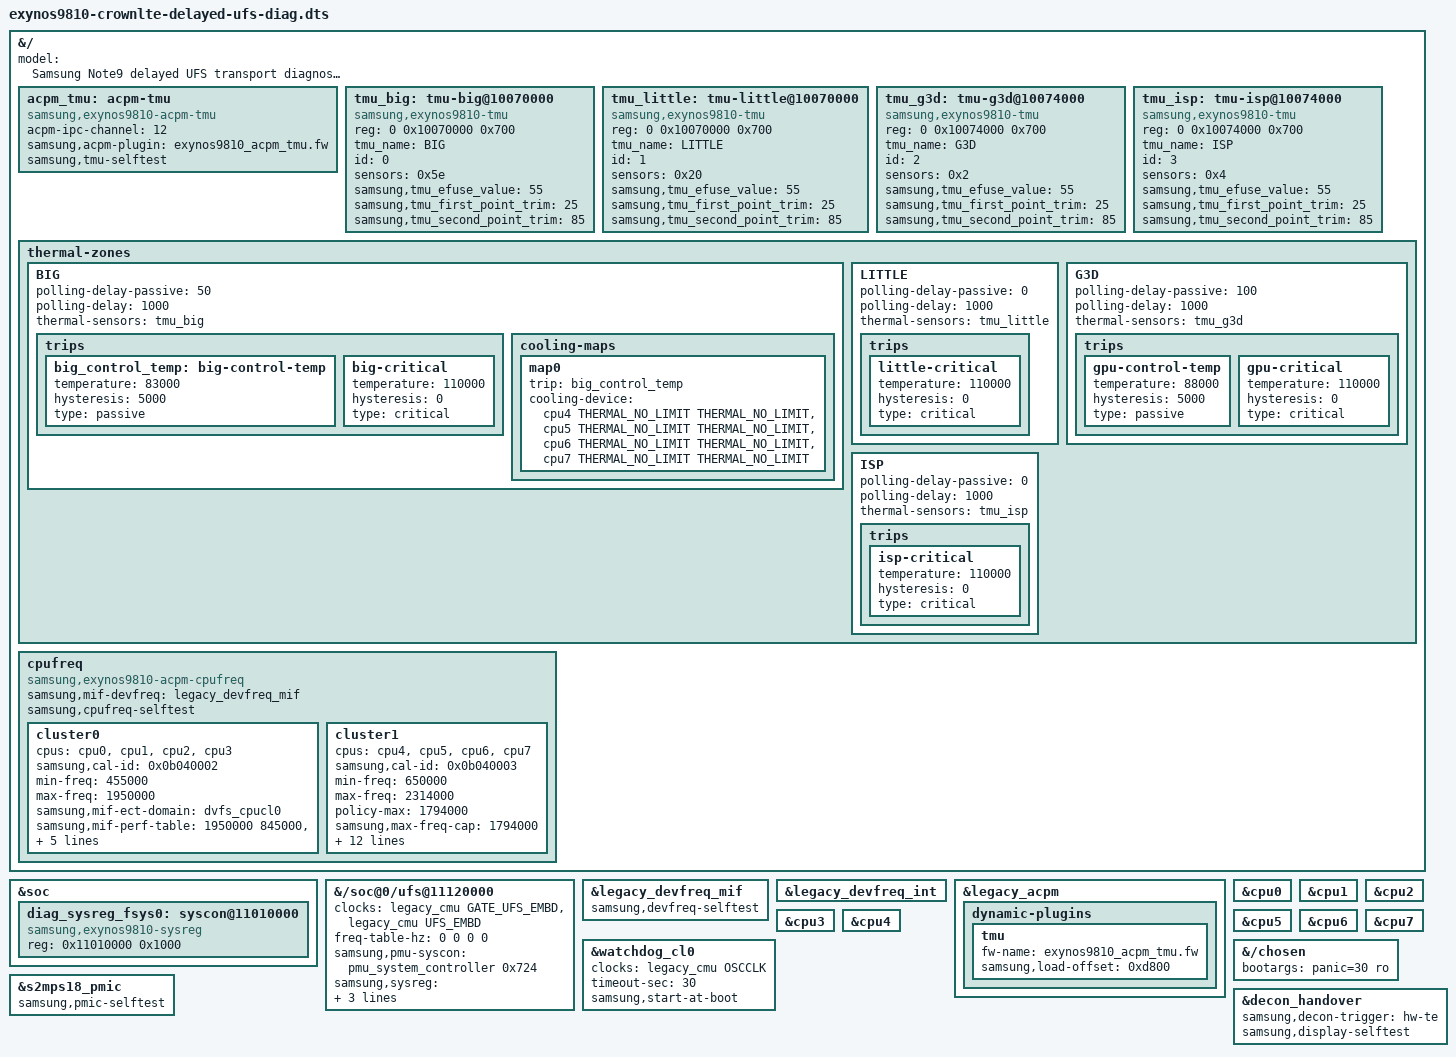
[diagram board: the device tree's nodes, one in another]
// SPDX-License-Identifier: GPL-2.0
/* First-probe gate and SCSI policy are mandatory. No Android init or mounts.
 * VCC and pad mux are inherited from sboot for this first transport test.
 * No regulator driver is enabled in the parent diagnostic configuration. */
#include "exynos9810-crownlte-real-clock-usb-diag.dts"
#include <dt-bindings/thermal/thermal.h>

&{/} {
	model = "Samsung Note9 delayed UFS transport diagnostic";
};
&soc {
	diag_sysreg_fsys0: syscon@11010000 {
		compatible = "samsung,exynos9810-sysreg", "syscon";
		reg = <0x11010000 0x1000>;
	};
};
&{/soc@0/ufs@11120000} {
	clocks = <&legacy_cmu GATE_UFS_EMBD>, <&legacy_cmu UFS_EMBD>;
	clock-names = "GATE_UFS_EMBD", "UFS_EMBD";
	freq-table-hz = <0 0 0 0>;
	samsung,pmu-syscon = <&pmu_system_controller 0x724>;
	samsung,sysreg = <&diag_sysreg_fsys0 0x700 0x300 0x300>;
	dma-coherent;
	crownlte,read-only-diagnostic;
	status = "okay";
};

/*
 * MIF/INT devfreq. The self-test runs at ~105 s uptime: tables, CMU
 * readback, MIF/INT to max and to the lowest floor-safe level and back,
 * ACPM MIF requests.
 */
&legacy_devfreq_mif {
	samsung,devfreq-selftest;
	status = "okay";
};
&legacy_devfreq_int { status = "okay"; };

/*
 * ACPM TMU plugin and TMU temperature sensors (4.9 exynos_acpm_tmu +
 * exynos_tmu, crownlte_eur_open_26 DT). When the boot leaves the TMU plugin
 * detached (is_attached=0, stay_attached=1), plugins_init() loads the
 * built-in image at the descriptor's base and sends DP_A on channel 4. The
 * ihex image is linked at 0xd800; any other descriptor base is refused.
 */
&legacy_acpm {
	dynamic-plugins {
		tmu {
			fw-name = "exynos9810_acpm_tmu.fw";
			samsung,load-offset = <0xd800>;
		};
	};
};

&{/} {
	acpm_tmu: acpm-tmu {
		compatible = "samsung,exynos9810-acpm-tmu";
		acpm-ipc-channel = <12>;
		samsung,acpm-plugin = "exynos9810_acpm_tmu.fw";
		samsung,tmu-selftest;
	};

	/* Register blocks are shared pairwise and only read, never written. */
	tmu_big: tmu-big@10070000 {
		compatible = "samsung,exynos9810-tmu";
		reg = <0 0x10070000 0x700>;
		tmu_name = "BIG";
		id = <0>;
		sensors = <0x5e>;
		#thermal-sensor-cells = <0>;
		samsung,tmu_efuse_value = <55>;
		samsung,tmu_first_point_trim = <25>;
		samsung,tmu_second_point_trim = <85>;
	};

	tmu_little: tmu-little@10070000 {
		compatible = "samsung,exynos9810-tmu";
		reg = <0 0x10070000 0x700>;
		tmu_name = "LITTLE";
		id = <1>;
		sensors = <0x20>;
		#thermal-sensor-cells = <0>;
		samsung,tmu_efuse_value = <55>;
		samsung,tmu_first_point_trim = <25>;
		samsung,tmu_second_point_trim = <85>;
	};

	tmu_g3d: tmu-g3d@10074000 {
		compatible = "samsung,exynos9810-tmu";
		reg = <0 0x10074000 0x700>;
		tmu_name = "G3D";
		id = <2>;
		sensors = <0x2>;
		#thermal-sensor-cells = <0>;
		samsung,tmu_efuse_value = <55>;
		samsung,tmu_first_point_trim = <25>;
		samsung,tmu_second_point_trim = <85>;
	};

	tmu_isp: tmu-isp@10074000 {
		compatible = "samsung,exynos9810-tmu";
		reg = <0 0x10074000 0x700>;
		tmu_name = "ISP";
		id = <3>;
		sensors = <0x4>;
		#thermal-sensor-cells = <0>;
		samsung,tmu_efuse_value = <55>;
		samsung,tmu_first_point_trim = <25>;
		samsung,tmu_second_point_trim = <85>;
	};

	/*
	 * 4.9 passive control temperatures (BIG 83 C, G3D 88 C; LITTLE/ISP had
	 * none). 4.9's "hot" trip was 115 C and became the TMU rise7/hardware
	 * trip; the software critical trip sits below it. 4.9 throttled BIG
	 * with power_allocator over the big cpufreq domain at big-control-temp
	 * (cooling-device <&domain1 NO_LIMIT NO_LIMIT>). Without an energy model
	 * power_allocator cannot drive cpufreq cooling here, so BIG uses the
	 * default step_wise governor on the same trip and cooling range.
	 * 4.9's LITTLE maps were all <0 0> (never throttle) and are omitted;
	 * G3D has no devfreq cooling device yet.
	 * 4.9 LITTLE/ISP/G3D relied on TMU interrupts; here everything polls.
	 */
	thermal-zones {
		BIG {
			polling-delay-passive = <50>;
			polling-delay = <1000>;
			thermal-sensors = <&tmu_big>;

			trips {
				big_control_temp: big-control-temp {
					temperature = <83000>;
					hysteresis = <5000>;
					type = "passive";
				};
				big-critical {
					temperature = <110000>;
					hysteresis = <0>;
					type = "critical";
				};
			};

			cooling-maps {
				map0 {
					trip = <&big_control_temp>;
					cooling-device =
						<&cpu4 THERMAL_NO_LIMIT THERMAL_NO_LIMIT>,
						<&cpu5 THERMAL_NO_LIMIT THERMAL_NO_LIMIT>,
						<&cpu6 THERMAL_NO_LIMIT THERMAL_NO_LIMIT>,
						<&cpu7 THERMAL_NO_LIMIT THERMAL_NO_LIMIT>;
				};
			};
		};

		LITTLE {
			polling-delay-passive = <0>;
			polling-delay = <1000>;
			thermal-sensors = <&tmu_little>;

			trips {
				little-critical {
					temperature = <110000>;
					hysteresis = <0>;
					type = "critical";
				};
			};
		};

		G3D {
			polling-delay-passive = <100>;
			polling-delay = <1000>;
			thermal-sensors = <&tmu_g3d>;

			trips {
				gpu-control-temp {
					temperature = <88000>;
					hysteresis = <5000>;
					type = "passive";
				};
				gpu-critical {
					temperature = <110000>;
					hysteresis = <0>;
					type = "critical";
				};
			};
		};

		ISP {
			polling-delay-passive = <0>;
			polling-delay = <1000>;
			thermal-sensors = <&tmu_isp>;

			trips {
				isp-critical {
					temperature = <110000>;
					hysteresis = <0>;
					type = "critical";
				};
			};
		};
	};
};

/*
 * CPU frequency scaling: values from the 4.9 crownlte_eur_open_26 DT
 * cpufreq/domain@0 and domain@1. cal-id 0x0b040002/0x0b040003 are the ACPM
 * DVFS vclks dvfs_cpucl0/dvfs_cpucl1; 0x0b040000 is dvfs_mif. 4.9 gave big
 * max-freq 2314000 with policy-max 1794000; samsung,max-freq-cap (not in
 * 4.9) holds the table at 1794000 until thermal throttling is verified.
 * The mif-perf tables only drive a samsung,mif-devfreq supplier (none yet).
 * The cpufreq core registers each policy CPU node as a cooling device.
 */
&cpu0 { #cooling-cells = <2>; };
&cpu1 { #cooling-cells = <2>; };
&cpu2 { #cooling-cells = <2>; };
&cpu3 { #cooling-cells = <2>; };
&cpu4 { #cooling-cells = <2>; };
&cpu5 { #cooling-cells = <2>; };
&cpu6 { #cooling-cells = <2>; };
&cpu7 { #cooling-cells = <2>; };

&{/} {
	cpufreq {
		compatible = "samsung,exynos9810-acpm-cpufreq";
		/* CPU levels raise a MIF floor through the MIF devfreq (4.9 mif-perf). */
		samsung,mif-devfreq = <&legacy_devfreq_mif>;
		/* Diagnostic: exercise both clusters at ~100 s uptime. */
		samsung,cpufreq-selftest;

		cluster0 {
			cpus = <&cpu0>, <&cpu1>, <&cpu2>, <&cpu3>;
			samsung,cal-id = <0x0b040002>;
			min-freq = <455000>;
			max-freq = <1950000>;
			samsung,mif-ect-domain = "dvfs_cpucl0";
			samsung,mif-perf-table =
				<1950000 845000>, <1794000 845000>,
				<1690000 845000>, <1456000 676000>,
				<1248000 676000>, <1053000 676000>,
				<949000 676000>, <832000 546000>,
				<715000 546000>, <598000 421000>,
				<455000 0>;
		};

		cluster1 {
			cpus = <&cpu4>, <&cpu5>, <&cpu6>, <&cpu7>;
			samsung,cal-id = <0x0b040003>;
			min-freq = <650000>;
			max-freq = <2314000>;
			policy-max = <1794000>;
			samsung,max-freq-cap = <1794000>;
			samsung,mif-ect-domain = "dvfs_cpucl1";
			samsung,mif-perf-table =
				<2886000 1794000>, <2860000 1794000>,
				<2704000 1794000>, <2652000 1794000>,
				<2496000 1794000>, <2314000 1794000>,
				<2106000 1794000>, <2002000 1794000>,
				<1924000 1794000>, <1794000 1794000>,
				<1690000 1539000>, <1586000 1014000>,
				<1469000 845000>, <1261000 676000>,
				<1170000 676000>, <1066000 676000>,
				<962000 546000>, <858000 546000>,
				<741000 421000>, <650000 421000>,
				<598000 421000>;
		};
	};
};

/*
 * CL0 hardware watchdog, armed at subsys_initcall and pinged by the kernel
 * (WATCHDOG_HANDLE_BOOT_ENABLED, OPEN_TIMEOUT=0) for as long as no process
 * opens /dev/watchdog. A hang then ends in a CLUSTER0 watchdog reset; with
 * the boot shim's normal INFORM2/INFORM3 and SBOOT's upload policy off
 * (PARAM FORCE_UPLOAD=0, DEBUG_LEVEL low) SBOOT boots the normal BOOT image.
 * The driver refuses to arm (and logs why) unless INFORM2/3 are normal, DFD
 * dump-GPR and every WDT reset-disable bit are clear, the counter runs at
 * OSCCLK/2048 within 10%, and the PMU reset unmask reads back.
 * Only OSCCLK is claimed: enabling/releasing a PERIS bus vclk would switch
 * the PERIS user mux (GIC/MCT bus). The bus itself is always on.
 * The expiry selftest is a separate DTB: exynos9810-crownlte-delayed-ufs-wdt-selftest-diag.
 */
&watchdog_cl0 {
	clocks = <&legacy_cmu OSCCLK>;
	clock-names = "watchdog";
	timeout-sec = <30>;
	samsung,start-at-boot;
	status = "okay";
};

/* SMP bring-up test: all eight CPUs */
&{/chosen} { bootargs = "panic=30 ro"; };

/*
 * S2MPS18 PMIC + RTC, first trial read-only: no samsung,rtc-read-latch and
 * no samsung,rtc-write-enable, so the transport write policy is sealed empty
 * and nothing is written to the PMIC. The self-test at ~106 s logs the chip
 * id, status and regulator registers and two RTC reads 1 s apart.
 */
&s2mps18_pmic {
	samsung,pmic-selftest;
	status = "okay";
};

/*
 * Display stage 1: simplefb console on SBoot's scanout buffer. The only DPU
 * register write is the 4.9 decon_reg_set_trigger(HW, ENABLE) RMW of DECON-F
 * HW_SW_TRIG_CONTROL (set HW_TRIG_EN, clear HW_TRIG_MASK_DECON), done only
 * after the scanout is verified; restored on shutdown. Self-test pattern at
 * ~108 s, held 10 s ("display selftest:").
 */
&decon_handover {
	samsung,decon-trigger = "hw-te";
	samsung,display-selftest;
};
